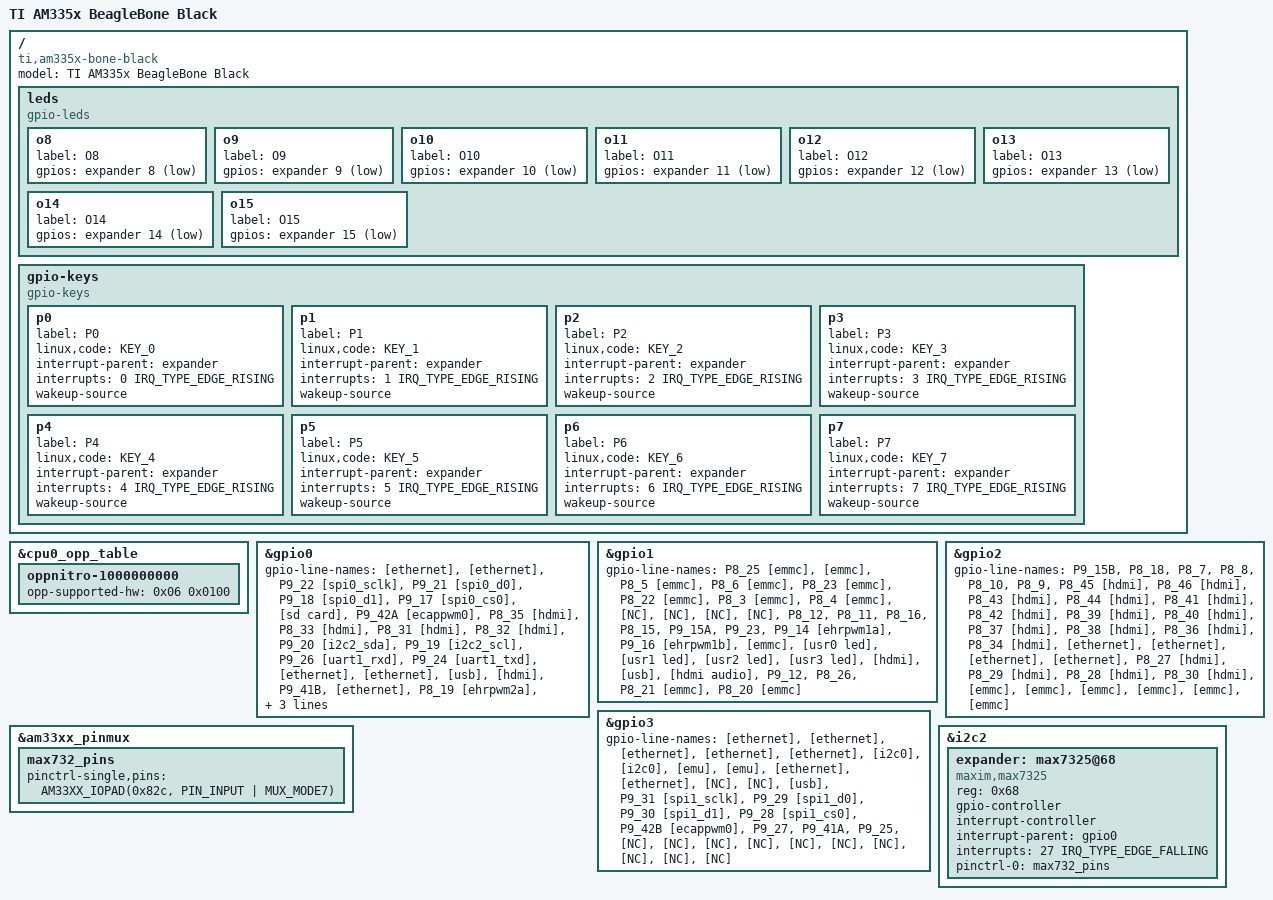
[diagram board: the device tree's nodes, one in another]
// SPDX-License-Identifier: GPL-2.0-only
/*
 * Copyright (C) 2012 Texas Instruments Incorporated - https://www.ti.com/
 */
/dts-v1/;

#include "am33xx.dtsi"
#include "am335x-bone-common.dtsi"
#include "am335x-boneblack-common.dtsi"
#include <dt-bindings/input/input.h>

/ {
	model = "TI AM335x BeagleBone Black";
	compatible = "ti,am335x-bone-black", "ti,am335x-bone", "ti,am33xx";
};

&cpu0_opp_table {
	/*
	 * All PG 2.0 silicon may not support 1GHz but some of the early
	 * BeagleBone Blacks have PG 2.0 silicon which is guaranteed
	 * to support 1GHz OPP so enable it for PG 2.0 on this board.
	 */
	oppnitro-1000000000 {
		opp-supported-hw = <0x06 0x0100>;
	};
};

&gpio0 {
	gpio-line-names =
		"[ethernet]",
		"[ethernet]",
		"P9_22 [spi0_sclk]",
		"P9_21 [spi0_d0]",
		"P9_18 [spi0_d1]",
		"P9_17 [spi0_cs0]",
		"[sd card]",
		"P9_42A [ecappwm0]",
		"P8_35 [hdmi]",
		"P8_33 [hdmi]",
		"P8_31 [hdmi]",
		"P8_32 [hdmi]",
		"P9_20 [i2c2_sda]",
		"P9_19 [i2c2_scl]",
		"P9_26 [uart1_rxd]",
		"P9_24 [uart1_txd]",
		"[ethernet]",
		"[ethernet]",
		"[usb]",
		"[hdmi]",
		"P9_41B",
		"[ethernet]",
		"P8_19 [ehrpwm2a]",
		"P8_13 [ehrpwm2b]",
		"[NC]",
		"[NC]",
		"P8_14",
		"P8_17",
		"[ethernet]",
		"[ethernet]",
		"P9_11 [uart4_rxd]",
		"P9_13 [uart4_txd]";
};

&gpio1 {
	gpio-line-names =
		"P8_25 [emmc]",
		"[emmc]",
		"P8_5 [emmc]",
		"P8_6 [emmc]",
		"P8_23 [emmc]",
		"P8_22 [emmc]",
		"P8_3 [emmc]",
		"P8_4 [emmc]",
		"[NC]",
		"[NC]",
		"[NC]",
		"[NC]",
		"P8_12",
		"P8_11",
		"P8_16",
		"P8_15",
		"P9_15A",
		"P9_23",
		"P9_14 [ehrpwm1a]",
		"P9_16 [ehrpwm1b]",
		"[emmc]",
		"[usr0 led]",
		"[usr1 led]",
		"[usr2 led]",
		"[usr3 led]",
		"[hdmi]",
		"[usb]",
		"[hdmi audio]",
		"P9_12",
		"P8_26",
		"P8_21 [emmc]",
		"P8_20 [emmc]";
};

&gpio2 {
	gpio-line-names =
		"P9_15B",
		"P8_18",
		"P8_7",
		"P8_8",
		"P8_10",
		"P8_9",
		"P8_45 [hdmi]",
		"P8_46 [hdmi]",
		"P8_43 [hdmi]",
		"P8_44 [hdmi]",
		"P8_41 [hdmi]",
		"P8_42 [hdmi]",
		"P8_39 [hdmi]",
		"P8_40 [hdmi]",
		"P8_37 [hdmi]",
		"P8_38 [hdmi]",
		"P8_36 [hdmi]",
		"P8_34 [hdmi]",
		"[ethernet]",
		"[ethernet]",
		"[ethernet]",
		"[ethernet]",
		"P8_27 [hdmi]",
		"P8_29 [hdmi]",
		"P8_28 [hdmi]",
		"P8_30 [hdmi]",
		"[emmc]",
		"[emmc]",
		"[emmc]",
		"[emmc]",
		"[emmc]",
		"[emmc]";
};

&gpio3 {
	gpio-line-names =
		"[ethernet]",
		"[ethernet]",
		"[ethernet]",
		"[ethernet]",
		"[ethernet]",
		"[i2c0]",
		"[i2c0]",
		"[emu]",
		"[emu]",
		"[ethernet]",
		"[ethernet]",
		"[NC]",
		"[NC]",
		"[usb]",
		"P9_31 [spi1_sclk]",
		"P9_29 [spi1_d0]",
		"P9_30 [spi1_d1]",
		"P9_28 [spi1_cs0]",
		"P9_42B [ecappwm0]",
		"P9_27",
		"P9_41A",
		"P9_25",
		"[NC]",
		"[NC]",
		"[NC]",
		"[NC]",
		"[NC]",
		"[NC]",
		"[NC]",
		"[NC]",
		"[NC]",
		"[NC]";
};

&am33xx_pinmux {
	max732_pins: max732_pins {
		pinctrl-single,pins = <
			AM33XX_IOPAD(0x82c, PIN_INPUT | MUX_MODE7)		/* gpmc_ad11.gpio0_27 */
		>;
	};
};

/* i2c2_pins are already muxed, i2c2.status is okay, driver is built-in */
&i2c2 {
	expander: max7325@68 {
		compatible = "maxim,max7325";
		reg = <0x68>;
		gpio-controller;
		#gpio-cells = <2>;

		interrupt-controller;
		#interrupt-cells = <2>;
		interrupt-parent = <&gpio0>;
		interrupts = <27 IRQ_TYPE_EDGE_FALLING>;

		pinctrl-names = "default";
		pinctrl-0 = <&max732_pins>;
	};
};

/ {
	leds {
		compatible = "gpio-leds";
		status = "okay";

		o8 {
			label = "O8";
			gpios = <&expander 8 GPIO_ACTIVE_LOW>;
		};

		o9 {
			label = "O9";
			gpios = <&expander 9 GPIO_ACTIVE_LOW>;
		};

		o10 {
			label = "O10";
			gpios = <&expander 10 GPIO_ACTIVE_LOW>;
		};

		o11 {
			label = "O11";
			gpios = <&expander 11 GPIO_ACTIVE_LOW>;
		};

		o12 {
			label = "O12";
			gpios = <&expander 12 GPIO_ACTIVE_LOW>;
		};

		o13 {
			label = "O13";
			gpios = <&expander 13 GPIO_ACTIVE_LOW>;
		};

		o14 {
			label = "O14";
			gpios = <&expander 14 GPIO_ACTIVE_LOW>;
		};

		o15 {
			label = "O15";
			gpios = <&expander 15 GPIO_ACTIVE_LOW>;
		};
	};

	gpio-keys {
		compatible = "gpio-keys";

		p0 {
			label = "P0";
			linux,code = <KEY_0>;
			interrupt-parent = <&expander>;
			interrupts = <0 IRQ_TYPE_EDGE_RISING>;
			wakeup-source;
		};

		p1 {
			label = "P1";
			linux,code = <KEY_1>;
			interrupt-parent = <&expander>;
			interrupts = <1 IRQ_TYPE_EDGE_RISING>;
			wakeup-source;
		};

		p2 {
			label = "P2";
			linux,code = <KEY_2>;
			interrupt-parent = <&expander>;
			interrupts = <2 IRQ_TYPE_EDGE_RISING>;
			wakeup-source;
		};

		p3 {
			label = "P3";
			linux,code = <KEY_3>;
			interrupt-parent = <&expander>;
			interrupts = <3 IRQ_TYPE_EDGE_RISING>;
			wakeup-source;
		};

		p4 {
			label = "P4";
			linux,code = <KEY_4>;
			interrupt-parent = <&expander>;
			interrupts = <4 IRQ_TYPE_EDGE_RISING>;
			wakeup-source;
		};

		p5 {
			label = "P5";
			linux,code = <KEY_5>;
			interrupt-parent = <&expander>;
			interrupts = <5 IRQ_TYPE_EDGE_RISING>;
			wakeup-source;
		};

		p6 {
			label = "P6";
			linux,code = <KEY_6>;
			interrupt-parent = <&expander>;
			interrupts = <6 IRQ_TYPE_EDGE_RISING>;
			wakeup-source;
		};

		p7 {
			label = "P7";
			linux,code = <KEY_7>;
			interrupt-parent = <&expander>;
			interrupts = <7 IRQ_TYPE_EDGE_RISING>;
			wakeup-source;
		};
	};
};
